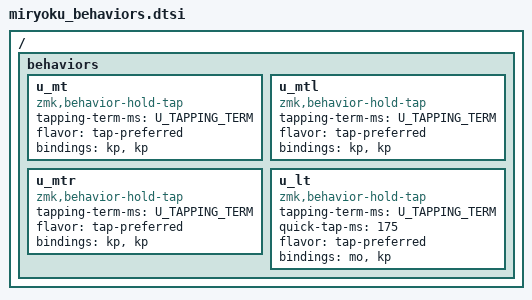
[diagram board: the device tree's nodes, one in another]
// Copyright 2022 Manna Harbour
// https://github.com/manna-harbour/miryoku

#define KEYS_L  0  1  2  3  4  5 \
               13 14 15 16 17 18 \
               28 29 30 31 32 33 34 \


#define KEYS_R  6 7  8  9 10 11 12 \
               19 20 21 22 23 24 25 26 27 \
               35 36 37 38 39 40 41 \

#define THUMBS 42 43 44 45 46 47

/ {
  behaviors {
    u_mt: u_mt {
      compatible = "zmk,behavior-hold-tap";
      #binding-cells = <2>;
      tapping-term-ms = <U_TAPPING_TERM>;
      flavor = "tap-preferred";
      bindings = <&kp>, <&kp>;
    };
    // // https://github.com/urob/zmk-config?tab=readme-ov-file#timeless-homerow-mods
    // u_mtl: u_mtl {
    //   compatible = "zmk,behavior-hold-tap";
    //   label = "u_mtl";
    //   #binding-cells = <2>;
    //   flavor = "balanced";
    //   tapping-term-ms = <U_TAPPING_TERM>;
    //   quick-tap-ms = <175>;
    //   require-prior-idle-ms = <150>;
    //   bindings = <&kp>, <&kp>;
    //   hold-trigger-key-positions = <KEYS_R THUMBS>;
    //   hold-trigger-on-release;
    // };
    // u_mtr: u_mtr {
    //   compatible = "zmk,behavior-hold-tap";
    //   label = "u_mtr";
    //   #binding-cells = <2>;
    //   flavor = "balanced";
    //   tapping-term-ms = <U_TAPPING_TERM>;
    //   quick-tap-ms = <175>;
    //   require-prior-idle-ms = <150>;
    //   bindings = <&kp>, <&kp>;
    //   hold-trigger-key-positions = <KEYS_L THUMBS>;
    //   hold-trigger-on-release;
    // };
    // passthrough u_mt to u_mtl
    u_mtl: u_mtl {
      compatible = "zmk,behavior-hold-tap";
      #binding-cells = <2>;
      tapping-term-ms = <U_TAPPING_TERM>;
      flavor = "tap-preferred";
      bindings = <&kp>, <&kp>;
    };
    u_mtr: u_mtr {
      compatible = "zmk,behavior-hold-tap";
      #binding-cells = <2>;
      tapping-term-ms = <U_TAPPING_TERM>;
      flavor = "tap-preferred";
      bindings = <&kp>, <&kp>;
    };
    u_lt: u_lt {
      compatible = "zmk,behavior-hold-tap";
      #binding-cells = <2>;
      tapping-term-ms = <U_TAPPING_TERM>;
      quick-tap-ms = <175>;
      flavor = "tap-preferred";
      bindings = <&mo>, <&kp>;
    };
  };
};
